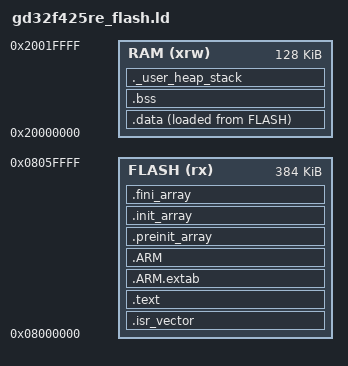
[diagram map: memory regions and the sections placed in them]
/* gd32f425re_flash.ld */
/* Linker script for GD32F425RET6 grblHAL port.
   Application starts at 0x0800_0000 (no bootloader). */

ENTRY(Reset_Handler)

MEMORY
{
  /* Last 128K sector (0x08060000, sector 7) is reserved for NVS/EEPROM emulation. */
  RAM (xrw)        : ORIGIN = 0x20000000, LENGTH = 128K
  FLASH (rx)       : ORIGIN = 0x08000000, LENGTH = 384K
}

_estack = ORIGIN(RAM) + LENGTH(RAM);
_Min_Heap_Size = 0x200;
_Min_Stack_Size = 0x400;

SECTIONS
{
  .isr_vector :
  {
    . = ALIGN(4);
    KEEP(*(.isr_vector))
    . = ALIGN(4);
  } > FLASH

  .text :
  {
    . = ALIGN(4);
    *(.text)
    *(.text*)
    *(.rodata)
    *(.rodata*)
    *(.glue_7)
    *(.glue_7t)
    KEEP (*(.init))
    KEEP (*(.fini))
    . = ALIGN(4);
    _etext = .;
  } > FLASH

  .ARM.extab :
  {
    *(.ARM.extab* .gnu.linkonce.armextab.*)
  } > FLASH

  .ARM :
  {
    __exidx_start = .;
    *(.ARM.exidx*)
    __exidx_end = .;
  } > FLASH

  /* C runtime init/fini tables - harmless for pure C today, but without these
     output sections any future C++ global constructor or
     __attribute__((constructor)) would be silently dropped. */
  .preinit_array :
  {
    PROVIDE_HIDDEN (__preinit_array_start = .);
    KEEP (*(.preinit_array*))
    PROVIDE_HIDDEN (__preinit_array_end = .);
  } > FLASH

  .init_array :
  {
    PROVIDE_HIDDEN (__init_array_start = .);
    KEEP (*(SORT(.init_array.*)))
    KEEP (*(.init_array*))
    PROVIDE_HIDDEN (__init_array_end = .);
  } > FLASH

  .fini_array :
  {
    PROVIDE_HIDDEN (__fini_array_start = .);
    KEEP (*(SORT(.fini_array.*)))
    KEEP (*(.fini_array*))
    PROVIDE_HIDDEN (__fini_array_end = .);
  } > FLASH

  _sidata = LOADADDR(.data);

  .data :
  {
    . = ALIGN(4);
    _sdata = .;
    *(.data)
    *(.data*)
    . = ALIGN(4);
    _edata = .;
  } > RAM AT > FLASH

  . = ALIGN(4);
  .bss :
  {
    _sbss = .;
    __bss_start__ = _sbss;
    *(.bss)
    *(.bss*)
    *(COMMON)
    . = ALIGN(4);
    _ebss = .;
    __bss_end__ = _ebss;
  } > RAM

  _end = .;
  PROVIDE(end = .);

  /* Reserve the minimum newlib heap and MSP stack margin so a RAM overflow
     is caught at link time (there is no ._user_heap_stack consumer at
     runtime - the MSP stack lives at the top of RAM, below _estack). */
  ._user_heap_stack (NOLOAD) :
  {
    . = ALIGN(8);
    . = . + _Min_Heap_Size;
    . = . + _Min_Stack_Size;
    . = ALIGN(8);
  } > RAM
}
